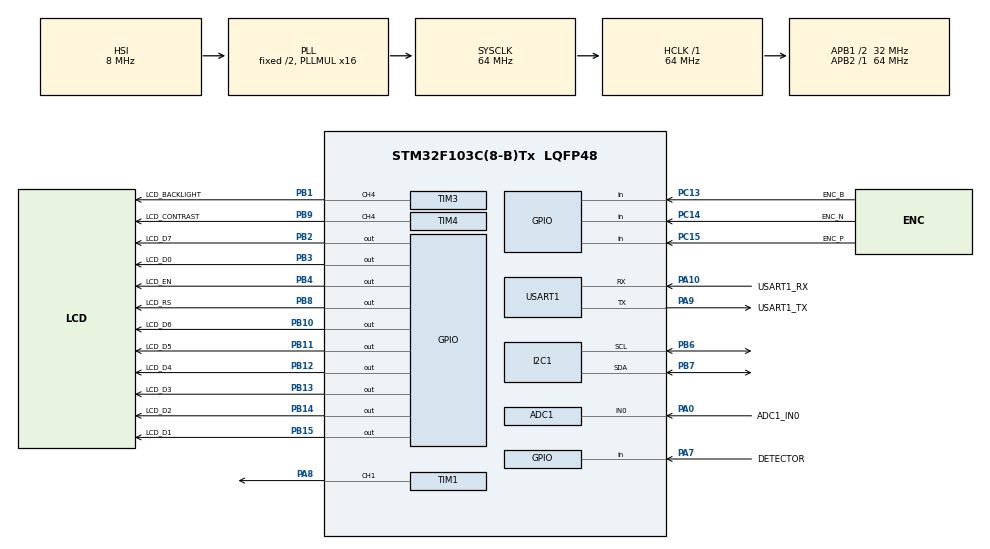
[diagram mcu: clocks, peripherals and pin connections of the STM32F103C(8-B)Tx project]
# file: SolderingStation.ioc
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ADC1.Channel-0\#ChannelRegularConversion=ADC_CHANNEL_0
ADC1.NbrOfConversionFlag=1
ADC1.Rank-0\#ChannelRegularConversion=1
ADC1.SamplingTime-0\#ChannelRegularConversion=ADC_SAMPLETIME_1CYCLE_5
ADC1.master=1
Mcu.Family=STM32F1
Mcu.Name=STM32F103C(8-B)Tx
Mcu.Package=LQFP48
Mcu.UserConstants=LCD_BACKLIGHT_CHANNEL,12;LCD_CONTRAST_CHANNEL,12
NVIC.PriorityGroup=NVIC_PRIORITYGROUP_4
NVIC.TIM2_IRQn=true\:0\:0\:false\:false\:true\:true
NVIC.USART1_IRQn=true\:0\:0\:false\:false\:true\:true
PA0-WKUP.GPIO_Label=ADC1_IN0
PA0-WKUP.Signal=ADCx_IN0
PA10.GPIO_Label=USART1_RX
PA10.Mode=Asynchronous
PA10.Signal=USART1_RX
PA13.Mode=Serial_Wire
PA13.Signal=SYS_JTMS-SWDIO
PA14.Mode=Serial_Wire
PA14.Signal=SYS_JTCK-SWCLK
PA7.GPIO_Label=DETECTOR
PA7.GPIO_PuPd=GPIO_PULLUP
PA7.Signal=GPIO_Input
PA8.Signal=S_TIM1_CH1
PA9.GPIO_Label=USART1_TX
PA9.Mode=Asynchronous
PA9.Signal=USART1_TX
PB1.GPIO_Label=LCD_BACKLIGHT
PB1.Signal=S_TIM3_CH4
PB10.GPIO_Label=LCD_D6
PB10.Signal=GPIO_Output
PB11.GPIO_Label=LCD_D5
PB11.Signal=GPIO_Output
PB12.GPIO_Label=LCD_D4
PB12.Signal=GPIO_Output
PB13.GPIO_Label=LCD_D3
PB13.Signal=GPIO_Output
PB14.GPIO_Label=LCD_D2
PB14.Signal=GPIO_Output
PB15.GPIO_Label=LCD_D1
PB15.Signal=GPIO_Output
PB2.GPIO_Label=LCD_D7
PB2.Signal=GPIO_Output
PB3.GPIO_Label=LCD_D0
PB3.Signal=GPIO_Output
PB4.GPIO_Label=LCD_EN
PB4.Signal=GPIO_Output
PB6.Mode=I2C
PB6.Signal=I2C1_SCL
PB7.Mode=I2C
PB7.Signal=I2C1_SDA
PB8.GPIO_Label=LCD_RS
PB8.Signal=GPIO_Output
PB9.GPIO_Label=LCD_CONTRAST
PB9.Signal=S_TIM4_CH4
PC13-TAMPER-RTC.GPIO_Label=ENC_B
PC13-TAMPER-RTC.GPIO_PuPd=GPIO_PULLUP
PC13-TAMPER-RTC.Signal=GPIO_Input
PC14-OSC32_IN.GPIO_Label=ENC_N
PC14-OSC32_IN.GPIO_PuPd=GPIO_PULLUP
PC14-OSC32_IN.Signal=GPIO_Input
PC15-OSC32_OUT.GPIO_Label=ENC_P
PC15-OSC32_OUT.GPIO_PuPd=GPIO_PULLUP
PC15-OSC32_OUT.Signal=GPIO_Input
ProjectManager.HeapSize=0x400
ProjectManager.StackSize=0x600
ProjectManager.TargetToolchain=SW4STM32
RCC.ADCPresc=RCC_ADCPCLK2_DIV8
RCC.AHBFreq_Value=64000000
RCC.APB1CLKDivider=RCC_HCLK_DIV2
RCC.APB1Freq_Value=32000000
RCC.APB1TimFreq_Value=64000000
RCC.APB2Freq_Value=64000000
RCC.APB2TimFreq_Value=64000000
RCC.HCLKFreq_Value=64000000
RCC.PLLMUL=RCC_PLL_MUL16
RCC.SYSCLKFreq_VALUE=64000000
RCC.SYSCLKSource=RCC_SYSCLKSOURCE_PLLCLK
RCC.USBFreq_Value=64000000
SH.ADCx_IN0.0=ADC1_IN0,IN0
SH.S_TIM1_CH1.0=TIM1_CH1,PWM Generation1 CH1
SH.S_TIM3_CH4.0=TIM3_CH4,PWM Generation4 CH4
SH.S_TIM4_CH4.0=TIM4_CH4,PWM Generation4 CH4
TIM1.Channel-PWM\ Generation1\ CH1=TIM_CHANNEL_1
TIM1.OCFastMode_PWM-PWM\ Generation1\ CH1=TIM_OCFAST_ENABLE
TIM1.OCIdleState_1=TIM_OCIDLESTATE_SET
TIM1.OCPolarity_1=TIM_OCPOLARITY_LOW
TIM1.Period=2000
TIM2.Period=6399
TIM3.Channel-PWM\ Generation4\ CH4=TIM_CHANNEL_4
TIM3.Period=100
TIM3.Prescaler=640
TIM4.Channel-PWM\ Generation4\ CH4=TIM_CHANNEL_4
TIM4.Period=100
TIM4.Prescaler=640
USART1.VirtualMode=VM_ASYNC
VP_IWDG_VS_IWDG.Mode=IWDG_Activate
VP_TIM1_VS_ClockSourceINT.Mode=Internal
VP_TIM2_VS_ClockSourceINT.Mode=Internal
board=SolderingStation

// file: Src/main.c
/**
  ******************************************************************************
  * @file           : main.c
  * @brief          : Main program body
  ******************************************************************************
  ** This notice applies to any and all portions of this file
  * that are not between comment pairs USER CODE BEGIN and
  * USER CODE END. Other portions of this file, whether
  * inserted by the user or by software development tools
  * are owned by their respective copyright owners.
  *
  * COPYRIGHT(c) 2018 STMicroelectronics
  *
  * Redistribution and use in source and binary forms, with or without modification,
  * are permitted provided that the following conditions are met:
  *   1. Redistributions of source code must retain the above copyright notice,
  *      this list of conditions and the following disclaimer.
  *   2. Redistributions in binary form must reproduce the above copyright notice,
  *      this list of conditions and the following disclaimer in the documentation
  *      and/or other materials provided with the distribution.
  *   3. Neither the name of STMicroelectronics nor the names of its contributors
  *      may be used to endorse or promote products derived from this software
  *      without specific prior written permission.
  *
  * THIS SOFTWARE IS PROVIDED BY THE COPYRIGHT HOLDERS AND CONTRIBUTORS "AS IS"
  * AND ANY EXPRESS OR IMPLIED WARRANTIES, INCLUDING, BUT NOT LIMITED TO, THE
  * IMPLIED WARRANTIES OF MERCHANTABILITY AND FITNESS FOR A PARTICULAR PURPOSE ARE
  * DISCLAIMED. IN NO EVENT SHALL THE COPYRIGHT HOLDER OR CONTRIBUTORS BE LIABLE
  * FOR ANY DIRECT, INDIRECT, INCIDENTAL, SPECIAL, EXEMPLARY, OR CONSEQUENTIAL
  * DAMAGES (INCLUDING, BUT NOT LIMITED TO, PROCUREMENT OF SUBSTITUTE GOODS OR
  * SERVICES; LOSS OF USE, DATA, OR PROFITS; OR BUSINESS INTERRUPTION) HOWEVER
  * CAUSED AND ON ANY THEORY OF LIABILITY, WHETHER IN CONTRACT, STRICT LIABILITY,
  * OR TORT (INCLUDING NEGLIGENCE OR OTHERWISE) ARISING IN ANY WAY OUT OF THE USE
  * OF THIS SOFTWARE, EVEN IF ADVISED OF THE POSSIBILITY OF SUCH DAMAGE.
  *
  ******************************************************************************
  */
#include "main.h"
#include "stm32f1xx_hal.h"
#include "adc.h"
#include "i2c.h"
#include "iwdg.h"
#include "tim.h"
#include "usart.h"
#include "gpio.h"

/* USER CODE BEGIN Includes */
#include "core_support.h"
/* USER CODE END Includes */

/* USER CODE BEGIN PV */
/* Private variables ---------------------------------------------------------*/

/* USER CODE END PV */

void SystemClock_Config(void);

/* USER CODE BEGIN PFP */
/* Private function prototypes -----------------------------------------------*/

/* USER CODE END PFP */

int main(void)
{

  /* MCU Configuration----------------------------------------------------------*/

  /* Reset of all peripherals, Initializes the Flash interface and the Systick. */
  HAL_Init();

  /* Configure the system clock */
  SystemClock_Config();

  /* Initialize all configured peripherals */
  MX_GPIO_Init();
  MX_ADC1_Init();
  MX_TIM1_Init();
  MX_USART1_UART_Init();
  MX_TIM3_Init();
  MX_TIM4_Init();
  MX_I2C1_Init();
  MX_TIM2_Init();
  MX_IWDG_Init();
  /* USER CODE BEGIN 2 */
    MY_main();
  /* USER CODE END 2 */

  /* Infinite loop */
    while (1) {

    }

}

void SystemClock_Config(void)
{

  RCC_OscInitTypeDef RCC_OscInitStruct;
  RCC_ClkInitTypeDef RCC_ClkInitStruct;
  RCC_PeriphCLKInitTypeDef PeriphClkInit;

    /**Initializes the CPU, AHB and APB busses clocks
    */
  RCC_OscInitStruct.OscillatorType = RCC_OSCILLATORTYPE_HSI|RCC_OSCILLATORTYPE_LSI;
  RCC_OscInitStruct.HSIState = RCC_HSI_ON;
  RCC_OscInitStruct.HSICalibrationValue = 16;
  RCC_OscInitStruct.LSIState = RCC_LSI_ON;
  RCC_OscInitStruct.PLL.PLLState = RCC_PLL_ON;
  RCC_OscInitStruct.PLL.PLLSource = RCC_PLLSOURCE_HSI_DIV2;
  RCC_OscInitStruct.PLL.PLLMUL = RCC_PLL_MUL16;
  if (HAL_RCC_OscConfig(&RCC_OscInitStruct) != HAL_OK)
  {
    _Error_Handler(__FILE__, __LINE__);
  }

    /**Initializes the CPU, AHB and APB busses clocks
    */
  RCC_ClkInitStruct.ClockType = RCC_CLOCKTYPE_HCLK|RCC_CLOCKTYPE_SYSCLK
                              |RCC_CLOCKTYPE_PCLK1|RCC_CLOCKTYPE_PCLK2;
  RCC_ClkInitStruct.SYSCLKSource = RCC_SYSCLKSOURCE_PLLCLK;
  RCC_ClkInitStruct.AHBCLKDivider = RCC_SYSCLK_DIV1;
  RCC_ClkInitStruct.APB1CLKDivider = RCC_HCLK_DIV2;
  RCC_ClkInitStruct.APB2CLKDivider = RCC_HCLK_DIV1;

  if (HAL_RCC_ClockConfig(&RCC_ClkInitStruct, FLASH_LATENCY_2) != HAL_OK)
  {
    _Error_Handler(__FILE__, __LINE__);
  }

  PeriphClkInit.PeriphClockSelection = RCC_PERIPHCLK_ADC;
  PeriphClkInit.AdcClockSelection = RCC_ADCPCLK2_DIV8;
  if (HAL_RCCEx_PeriphCLKConfig(&PeriphClkInit) != HAL_OK)
  {
    _Error_Handler(__FILE__, __LINE__);
  }

    /**Configure the Systick interrupt time
    */
  HAL_SYSTICK_Config(HAL_RCC_GetHCLKFreq()/1000);

    /**Configure the Systick
    */
  HAL_SYSTICK_CLKSourceConfig(SYSTICK_CLKSOURCE_HCLK);

  /* SysTick_IRQn interrupt configuration */
  HAL_NVIC_SetPriority(SysTick_IRQn, 0, 0);
}

void _Error_Handler(char *file, int line)
{
  /* USER CODE BEGIN Error_Handler_Debug */
  UNUSED(file);
  UNUSED(line);
  /* User can add his own implementation to report the HAL error return state */
  while(1)
  {
  }
  /* USER CODE END Error_Handler_Debug */
}

/************************ (C) COPYRIGHT STMicroelectronics *****END OF FILE****/
